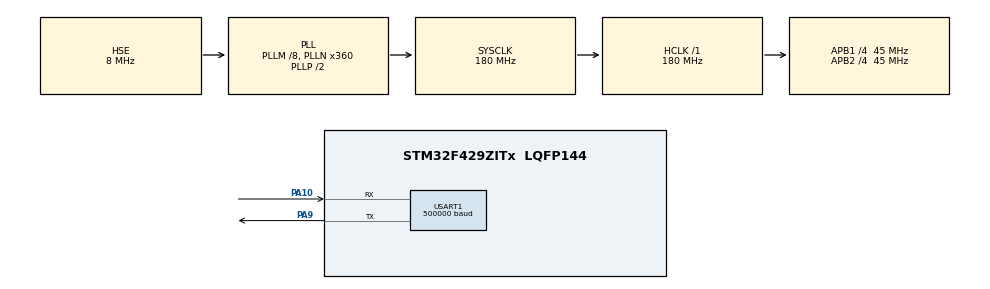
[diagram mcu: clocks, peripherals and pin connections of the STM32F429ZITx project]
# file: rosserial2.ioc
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Mcu.Family=STM32F4
RCC.PLLSourceVirtual=RCC_PLLSOURCE_HSE
Dma.USART1_RX.1.Instance=DMA2_Stream2
RCC.CortexFreq_Value=180000000
Dma.USART1_RX.1.MemDataAlignment=DMA_MDATAALIGN_BYTE
Dma.USART1_TX.0.MemInc=DMA_MINC_ENABLE
Dma.USART1_TX.0.PeriphInc=DMA_PINC_DISABLE
PA10.Mode=Asynchronous
USART1.BaudRate=500000
RCC.APB1CLKDivider=RCC_HCLK_DIV4
RCC.SYSCLKSource=RCC_SYSCLKSOURCE_PLLCLK
ProjectManager.StackSize=0x400
PA9.Mode=Asynchronous
Dma.USART1_TX.0.Priority=DMA_PRIORITY_HIGH
Dma.USART1_TX.0.Direction=DMA_MEMORY_TO_PERIPH
ProjectManager.TargetToolchain=STM32CubeIDE
PH0/OSC_IN.Mode=HSE-External-Oscillator
RCC.HCLKFreq_Value=180000000
RCC.APB2TimFreq_Value=90000000
PA9.Signal=USART1_TX
PH1/OSC_OUT.Signal=RCC_OSC_OUT
Dma.USART1_RX.1.MemInc=DMA_MINC_ENABLE
RCC.LSE_VALUE=32768
RCC.AHBFreq_Value=180000000
RCC.HSE_VALUE=8000000
Dma.USART1_RX.1.PeriphDataAlignment=DMA_PDATAALIGN_BYTE
Dma.USART1_RX.1.FIFOMode=DMA_FIFOMODE_DISABLE
Dma.USART1_TX.0.Mode=DMA_NORMAL
board=custom
RCC.VCOOutputFreq_Value=360000000
PH0/OSC_IN.Signal=RCC_OSC_IN
RCC.APB2Freq_Value=45000000
VP_TIM2_VS_ClockSourceINT.Mode=Internal
NVIC.TIM2_IRQn=true\:0\:0\:false\:false\:true\:true\:true
TIM2.Period=29999
Dma.USART1_TX.0.PeriphDataAlignment=DMA_PDATAALIGN_BYTE
PH1/OSC_OUT.Mode=HSE-External-Oscillator
Mcu.Name=STM32F429ZITx
Dma.USART1_RX.1.Mode=DMA_CIRCULAR
RCC.48MHZClocksFreq_Value=90000000
RCC.SYSCLKFreq_VALUE=180000000
Mcu.Package=LQFP144
TIM2.Prescaler=14
NVIC.DMA2_Stream7_IRQn=true\:0\:0\:false\:false\:true\:false\:true
RCC.EnbaleCSS=true
USART1.VirtualMode=VM_ASYNC
Dma.USART1_TX.0.MemDataAlignment=DMA_MDATAALIGN_BYTE
PA10.Signal=USART1_RX
ProjectManager.HeapSize=0x200
Dma.USART1_TX.0.Instance=DMA2_Stream7
Dma.USART1_TX.0.FIFOMode=DMA_FIFOMODE_DISABLE
RCC.HSI_VALUE=16000000
Dma.USART1_RX.1.PeriphInc=DMA_PINC_DISABLE
NVIC.PriorityGroup=NVIC_PRIORITYGROUP_4
RCC.APB2CLKDivider=RCC_HCLK_DIV4
NVIC.DMA2_Stream2_IRQn=true\:0\:0\:false\:false\:true\:false\:true
RCC.PLLM=8
RCC.PLLN=360
Dma.Request1=USART1_RX
RCC.APB1TimFreq_Value=90000000
Dma.USART1_RX.1.Direction=DMA_PERIPH_TO_MEMORY
Dma.USART1_RX.1.Priority=DMA_PRIORITY_HIGH
NVIC.USART1_IRQn=true\:0\:0\:false\:false\:true\:true\:true
RCC.APB1Freq_Value=45000000
Dma.Request0=USART1_TX

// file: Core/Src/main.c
/* USER CODE BEGIN Header */
/**
 ******************************************************************************
 * @file           : main.c
 * @brief          : Main program body
 ******************************************************************************
 * @attention
 *
 * <h2><center>&copy; Copyright (c) 2021 STMicroelectronics.
 * All rights reserved.</center></h2>
 *
 * This software component is licensed by ST under BSD 3-Clause license,
 * the "License"; You may not use this file except in compliance with the
 * License. You may obtain a copy of the License at:
 *                        opensource.org/licenses/BSD-3-Clause
 *
 ******************************************************************************
 */
/* USER CODE END Header */
#include "main.h"

/* USER CODE BEGIN Includes */
#include "mainpp.h"
/* USER CODE END Includes */

TIM_HandleTypeDef htim2;

UART_HandleTypeDef huart1;
DMA_HandleTypeDef hdma_usart1_tx;
DMA_HandleTypeDef hdma_usart1_rx;

void SystemClock_Config(void);
static void MX_GPIO_Init(void);
static void MX_DMA_Init(void);
static void MX_TIM2_Init(void);
static void MX_USART1_UART_Init(void);

/* USER CODE BEGIN 0 */
void HAL_TIM_PeriodElapsedCallback(TIM_HandleTypeDef *htim) {
    rosserial_task();
}
/* USER CODE END 0 */

int main(void)
{

  /* MCU Configuration--------------------------------------------------------*/

  /* Reset of all peripherals, Initializes the Flash interface and the Systick. */
  HAL_Init();

  /* Configure the system clock */
  SystemClock_Config();

  /* Initialize all configured peripherals */
  MX_GPIO_Init();
  MX_DMA_Init();
  MX_TIM2_Init();
  MX_USART1_UART_Init();
  /* USER CODE BEGIN 2 */
    rosserial_init();
    HAL_TIM_Base_Start_IT(&htim2);
    HAL_Delay(1000);
    roslog();
  /* USER CODE END 2 */

  /* Infinite loop */
    while (1) {

    }
}

void SystemClock_Config(void)
{
  RCC_OscInitTypeDef RCC_OscInitStruct = {0};
  RCC_ClkInitTypeDef RCC_ClkInitStruct = {0};

  /** Configure the main internal regulator output voltage
  */
  __HAL_RCC_PWR_CLK_ENABLE();
  __HAL_PWR_VOLTAGESCALING_CONFIG(PWR_REGULATOR_VOLTAGE_SCALE1);
  /** Initializes the RCC Oscillators according to the specified parameters
  * in the RCC_OscInitTypeDef structure.
  */
  RCC_OscInitStruct.OscillatorType = RCC_OSCILLATORTYPE_HSE;
  RCC_OscInitStruct.HSEState = RCC_HSE_ON;
  RCC_OscInitStruct.PLL.PLLState = RCC_PLL_ON;
  RCC_OscInitStruct.PLL.PLLSource = RCC_PLLSOURCE_HSE;
  RCC_OscInitStruct.PLL.PLLM = 8;
  RCC_OscInitStruct.PLL.PLLN = 360;
  RCC_OscInitStruct.PLL.PLLP = RCC_PLLP_DIV2;
  RCC_OscInitStruct.PLL.PLLQ = 4;
  if (HAL_RCC_OscConfig(&RCC_OscInitStruct) != HAL_OK)
  {
    Error_Handler();
  }
  /** Activate the Over-Drive mode
  */
  if (HAL_PWREx_EnableOverDrive() != HAL_OK)
  {
    Error_Handler();
  }
  /** Initializes the CPU, AHB and APB buses clocks
  */
  RCC_ClkInitStruct.ClockType = RCC_CLOCKTYPE_HCLK|RCC_CLOCKTYPE_SYSCLK
                              |RCC_CLOCKTYPE_PCLK1|RCC_CLOCKTYPE_PCLK2;
  RCC_ClkInitStruct.SYSCLKSource = RCC_SYSCLKSOURCE_PLLCLK;
  RCC_ClkInitStruct.AHBCLKDivider = RCC_SYSCLK_DIV1;
  RCC_ClkInitStruct.APB1CLKDivider = RCC_HCLK_DIV4;
  RCC_ClkInitStruct.APB2CLKDivider = RCC_HCLK_DIV4;

  if (HAL_RCC_ClockConfig(&RCC_ClkInitStruct, FLASH_LATENCY_5) != HAL_OK)
  {
    Error_Handler();
  }
  /** Enables the Clock Security System
  */
  HAL_RCC_EnableCSS();
}

static void MX_TIM2_Init(void)
{

  TIM_ClockConfigTypeDef sClockSourceConfig = {0};
  TIM_MasterConfigTypeDef sMasterConfig = {0};

  htim2.Instance = TIM2;
  htim2.Init.Prescaler = 14;
  htim2.Init.CounterMode = TIM_COUNTERMODE_UP;
  htim2.Init.Period = 29999;
  htim2.Init.ClockDivision = TIM_CLOCKDIVISION_DIV1;
  htim2.Init.AutoReloadPreload = TIM_AUTORELOAD_PRELOAD_DISABLE;
  if (HAL_TIM_Base_Init(&htim2) != HAL_OK)
  {
    Error_Handler();
  }
  sClockSourceConfig.ClockSource = TIM_CLOCKSOURCE_INTERNAL;
  if (HAL_TIM_ConfigClockSource(&htim2, &sClockSourceConfig) != HAL_OK)
  {
    Error_Handler();
  }
  sMasterConfig.MasterOutputTrigger = TIM_TRGO_RESET;
  sMasterConfig.MasterSlaveMode = TIM_MASTERSLAVEMODE_DISABLE;
  if (HAL_TIMEx_MasterConfigSynchronization(&htim2, &sMasterConfig) != HAL_OK)
  {
    Error_Handler();
  }

}

static void MX_USART1_UART_Init(void)
{

  huart1.Instance = USART1;
  huart1.Init.BaudRate = 500000;
  huart1.Init.WordLength = UART_WORDLENGTH_8B;
  huart1.Init.StopBits = UART_STOPBITS_1;
  huart1.Init.Parity = UART_PARITY_NONE;
  huart1.Init.Mode = UART_MODE_TX_RX;
  huart1.Init.HwFlowCtl = UART_HWCONTROL_NONE;
  huart1.Init.OverSampling = UART_OVERSAMPLING_16;
  if (HAL_UART_Init(&huart1) != HAL_OK)
  {
    Error_Handler();
  }

}

static void MX_DMA_Init(void)
{

  /* DMA controller clock enable */
  __HAL_RCC_DMA2_CLK_ENABLE();

  /* DMA interrupt init */
  /* DMA2_Stream2_IRQn interrupt configuration */
  HAL_NVIC_SetPriority(DMA2_Stream2_IRQn, 0, 0);
  HAL_NVIC_EnableIRQ(DMA2_Stream2_IRQn);
  /* DMA2_Stream7_IRQn interrupt configuration */
  HAL_NVIC_SetPriority(DMA2_Stream7_IRQn, 0, 0);
  HAL_NVIC_EnableIRQ(DMA2_Stream7_IRQn);

}

static void MX_GPIO_Init(void)
{

  /* GPIO Ports Clock Enable */
  __HAL_RCC_GPIOH_CLK_ENABLE();
  __HAL_RCC_GPIOA_CLK_ENABLE();

}

void Error_Handler(void)
{
    __disable_irq();
    while (1) {
    }
}

/************************ (C) COPYRIGHT STMicroelectronics *****END OF FILE****/
